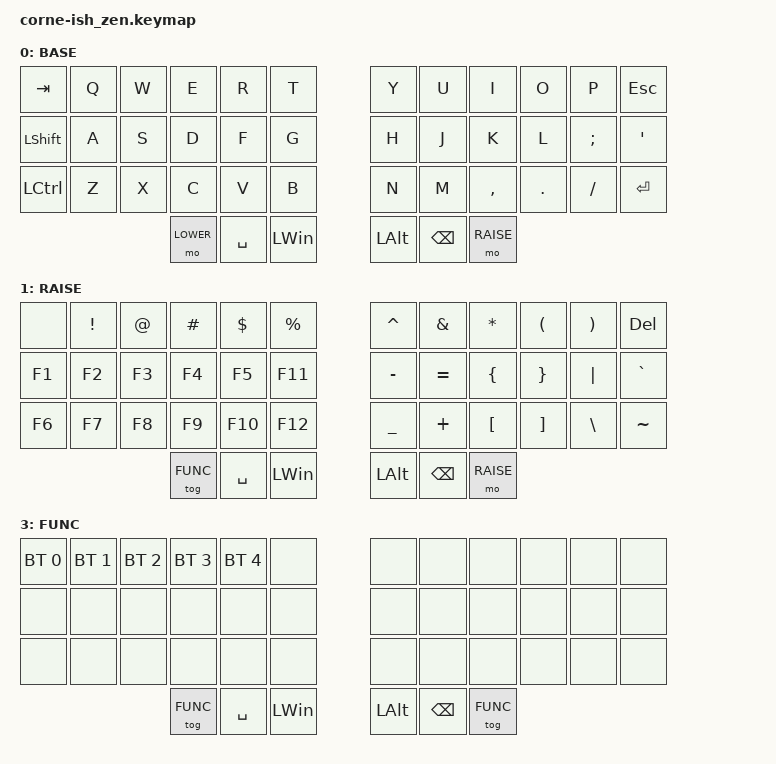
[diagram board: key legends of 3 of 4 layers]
/*
*
* Copyright (c) 2021 Darryl deHaan
* SPDX-License-Identifier: MIT
*
*/

#include <behaviors.dtsi>
#include <dt-bindings/zmk/keys.h>
#include <dt-bindings/zmk/bt.h>

#define BASE   0
#define RAISE  1
#define LOWER  2
#define FUNC   3

#define JIME	LA(GRAVE)
#define DSKR	LC(LG(RIGHT))
#define DSKL	LC(LG(LEFT))
#define MCPY	LC(C)
#define MPST	LC(V)
#define RERE	LC(R)
#define BT0		&bt BT_SEL 0
#define BT1		&bt BT_SEL 1
#define BT2		&bt BT_SEL 2
#define BT3		&bt BT_SEL 3
#define BT4		&bt BT_SEL 4


// -----------+----------+----------+----------+----------+----------+----+----------+----------+----------+----------+----------+----------+
// |          |          |          |          |          |          |    |          |          |          |          |          |          |
// |          |          |          |          |          |          |    |          |          |          |          |          |          |
// |          |          |          |          |          |          |    |          |          |          |          |          |          |
// +----------+----------+----------|          |          |          |    |          |          |          |----------+----------+----------+
//                                  +----------+----------+----------+    +----------+----------+----------+
/ {
        keymap {
                compatible = "zmk,keymap";

                default_layer {
                        label = "BASE";
                        bindings = <
// -----------+----------+----------+----------+----------+----------+----+----------+----------+----------+----------+----------+----------+
// |  TAB     |  Q       |  W       |  E       |  R       |  T       |    |  Y       |  U       |  I       |  O       |  P       | ESC      |
// |  SHFT    |  A       |  S       |  D       |  F       |  G       |    |  H       |  J       |  K       |  L       |  ;       |  '       |
// |  CTRL    |  Z       |  X       |  C       |  V       |  B       |    |  N       |  M       |  ,       |  .       |  /       | RET      |
// +----------+----------+----------|  LWR     |  BKSP    |  WIN     |    |  ALT     |  SPC     |  RSE     |----------+----------+----------+
//                                  +----------+----------+----------+    +----------+----------+----------+
   &kp TAB    &kp Q      &kp W      &kp E      &kp R      &kp T           &kp Y      &kp U      &kp I      &kp O      &kp P      &kp ESC
   &kp LSHFT  &kp A      &kp S      &kp D      &kp F      &kp G           &kp H      &kp J      &kp K      &kp L      &kp SEMI   &kp SQT
   &kp LCTL   &kp Z      &kp X      &kp C      &kp V      &kp B           &kp N      &kp M      &kp COMMA  &kp DOT    &kp FSLH   &kp RET
                                    &mo LOWER  &kp SPACE  &kp LWIN        &kp LALT   &kp BSPC   &mo RAISE
                        >;
                };

                raise_layer {
                        label = "RAISE";
                        bindings = <
// -----------+----------+----------+----------+----------+----------+----+----------+----------+----------+----------+----------+----------+
// |          |  !       |  @       |  #       |  $       |  %       |    |  ^       |  &       |  *       |  (       |  )       |  DEL     |
// |   F1     |  F2      |  F3      |  F4      |  F5      |  F11     |    |  -       |  =       |  [       |  ]       |  |       |  `       |
// |   F6     |  F7      |  F8      |  F9      |  F10     |  F12     |    |  _       |  +       |  {       |  }       |  \       |  ~       |
// +----------+----------+----------|  FUNC    |  BKSP    |  WIN     |    |  ALT     |  SPC     |  RSE     |----------+----------+----------+
//                                  +----------+----------+----------+    +----------+----------+----------+
   &none      &kp EXCL   &kp AT     &kp HASH   &kp DLLR   &kp PRCNT       &kp CARET  &kp AMPS   &kp ASTRK  &kp LPAR   &kp RPAR   &kp DEL  
   &kp F1     &kp F2     &kp F3     &kp F4     &kp F5     &kp F11         &kp MINUS  &kp EQUAL  &kp LBRC   &kp RBRC   &kp PIPE   &kp GRAVE  
   &kp F6     &kp F7     &kp F8     &kp F9     &kp F10    &kp F12         &kp UNDER  &kp PLUS   &kp LBKT   &kp RBKT   &kp BSLH   &kp TILDE  
                                    &tog FUNC  &kp SPACE  &kp LWIN        &kp LALT   &kp BSPC   &mo RAISE
                        >;
                };

                lower_layer {
                        label = "LOWER";
                        bindings = <
// -----------+----------+----------+----------+----------+----------+----+----------+----------+----------+----------+----------+----------+
// |          |  1       |  2       |  3       |  4       |  5       |    |  6       |  7       |  8       |  9       |  0       |  DEL     |
// |  DSKL    |  HOME    |          |  ↑       |          |  PGUP    |    |  INS     |  CTRL-C  |  CTRL-V  |  CTRL-R  |          |  PSCRN   |
// |  DSKR    |  END     |  ←       |  ↓       |  →       |  PGDN    |    |  DEL     |          |          |          |          |          |
// +----------+----------+----------|  LWR     |  BKSP    |  WIN     |    |  ALT     |  SPC     |  FUNC    |----------+----------+----------+
//                                  +----------+----------+----------+    +----------+----------+----------+
   &none      &kp N1     &kp N2     &kp N3     &kp N4     &kp N5          &kp N6     &kp N7     &kp N8     &kp N9     &kp N0     &kp DEL
   &kp DSKL   &kp HOME   &none      &kp UP     &none      &kp PG_UP       &kp INS    &kp MCPY   &kp MPST   &kp RERE   &none      &kp PSCRN  
   &kp DSKR   &kp END    &kp LEFT   &kp DOWN   &kp RIGHT  &kp PG_DN       &kp DEL    &none      &none      &none      &none      &none      &none  
                                    &mo LOWER  &kp SPACE  &kp LWIN        &kp LALT   &kp BSPC   &tog FUNC
                        >;
                };
				
                adjust_layer {
                        label = "FUNC";
                        bindings = <
// -----------+----------+----------+----------+----------+----------+----+----------+----------+----------+----------+----------+----------+
// |  BT0     |  BT1     |  BT2     |  BT3     |  BT4     |          |    |          |          |          |          |          |          |
// |          |          |          |          |          |          |    |          |          |          |          |          |          |
// |          |          |          |          |          |          |    |          |          |          |          |          |          |
// +----------+----------+----------|          |  BKSP    |  GUI     |    |  ALT     |  SPC     |          |----------+----------+----------+
//                                  +----------+----------+----------+    +----------+----------+----------+
   BT0        BT1        BT2        BT3        BT4        &none           &none      &none      &none      &none      &none      &none  
   &none      &none      &none      &none      &none      &none           &none      &none      &none      &none      &none      &none  
   &none      &none      &none      &none      &none      &none           &none      &none      &none      &none      &none      &none  
                                    &tog FUNC  &kp SPACE  &kp LWIN        &kp LALT   &kp BSPC   &tog FUNC
                        >;
                };			
        };
};
